# CH32M030 register map
Vendor: WCH Ltd.; File version: 1.1
Registers are 32-bit, read-write, reset 0x0 unless marked. A register's access mark holds for its fields unless they carry their own. Offsets are from the block's base; [hi:lo] are bit positions; {n}, {i} and the like mark numbered series.

## DBG — Debug support
Base 0xE000D000
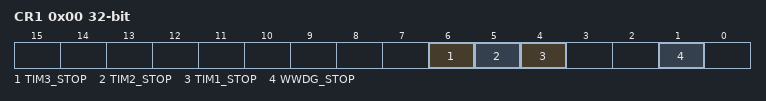
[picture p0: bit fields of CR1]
0x00 CR1 — DBGMCU_CFGR1
  [6] TIM3_STOP, [5] TIM2_STOP, [4] TIM1_STOP, [1] WWDG_STOP

## ESIG — Device electronic signature
Base 0x1FFFF3E0
0x00 FLACAP 16-bit ro — Flash capacity register
  [15:0] F_SIZE_15_0 — Flash size
{0x4+4i} UNIID{i} ro (i=1..3) — Unique identity {i}
  [31:0] U_ID_{32i-1}_{32i-32} — Unique identity[{32i-1}:{32i-32}]

## FLASH
Base 0x40022000
0x00 ACTLR — Flash key register
  [2:0] LATENCY — Number of FLASH wait states
0x04 KEYR wo — Flash key register
  [31:0] KEYR — FPEC key
0x08 OBTKEYR wo — Flash option key register
  [31:0] OBKEYR — Option byte key
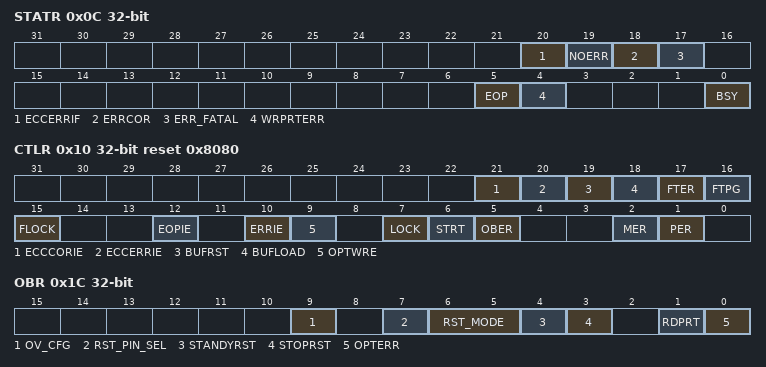
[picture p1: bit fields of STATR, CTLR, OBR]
0x0C STATR access per field — Status register
  [20] ECCERRIF rw — Flash module ECC verification error interrupt flag
  [19] NOERR ro — ECC verification of Flash module is error-free
  [18] ERRCOR ro — Flash module ECC verification error,error correction success
  [17] ERR_FATAL ro — Flash module ECC verification error,error correction success failure
  [5] EOP rw — End of operation
  [4] WRPRTERR rw — Write protection error
  [0] BSY ro — Busy
0x10 CTLR reset 0x8080 — Control register
  [21] ECCCORIE — ECC verification error occurs but correction is successful,ECC error flag location is selected
  [20] ECCERRIE — ECC error interrupt enabled
  [19] BUFRST — Buffer reset
  [18] BUFLOAD — Buffer load
  [17] FTER — Fast erase
  [16] FTPG — Fast programming
  [15] FLOCK — Fast programmable lock
  [12] EOPIE — End of operation interrupt enable
  [10] ERRIE — Error interrupt enable
  [9] OPTWRE — Option bytes lock
  [7] LOCK
  [6] STRT — Start
  [5] OBER — Option byte erase
  [2] MER — Mass Erase
  [1] PER — Page Erase
0x14 ADDR wo — Flash address register
  [31:0] FAR — Flash Address
0x1C OBR ro — Option byte register
  [9] OV_CFG — User configuration bit of the overvoltage protection detection function
  [7] RST_PIN_SEL — RESET PIN selection
  [6:5] RST_MODE — CFG_RST_MODE
  [4] STANDYRST
  [3] STOPRST
  [1] RDPRT — Read protection
  [0] OPTERR — Option byte error
0x20 WPR ro — Write protection register
  [31:0] WRP — Write protect
0x24 MODEKEYR wo — Mode select register
  [31:0] MODEKEYR — Mode select
0x28 BOOT_MODEKEYP wo — Boot mode key register
  [31:0] MODEKEYR — Boot mode key
0x2F CTLR2 8-bit — configuration register 2
  [6:5] VDD8_SEL — VDD voltage selection

## PFIC — Programmable Fast Interrupt Controller
Base 0xE000E000
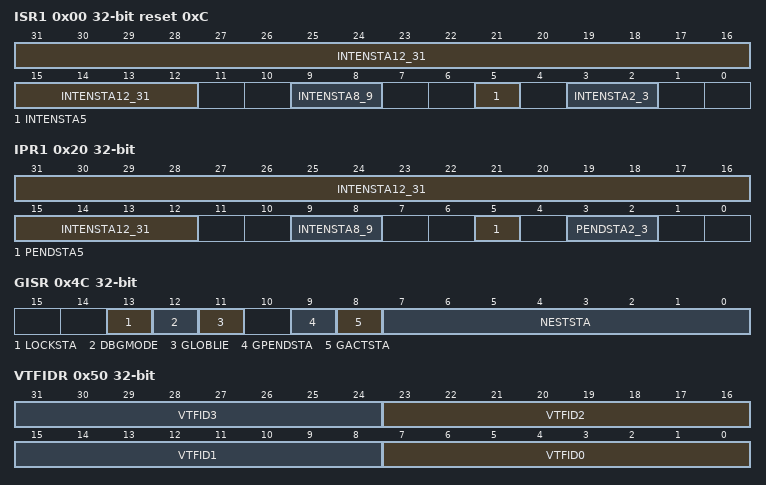
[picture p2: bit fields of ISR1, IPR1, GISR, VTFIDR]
0x00 ISR1 ro reset 0xC — Interrupt Status Register
  [31:12] INTENSTA12_31 — Interrupt ID Status
  [9:8] INTENSTA8_9 — Interrupt ID Status
  [5] INTENSTA5 — Interrupt ID Status
  [3:2] INTENSTA2_3 — Interrupt ID Status
0x04 ISR2 ro — Interrupt Status Register
  [14:0] INTENSTA — Interrupt ID Status
0x20 IPR1 ro — Interrupt Pending Register
  [31:12] INTENSTA12_31 — PENDSTA
  [9:8] INTENSTA8_9 — PENDSTA
  [5] PENDSTA5 — PENDSTA
  [3:2] PENDSTA2_3 — PENDSTA
0x24 IPR2 ro — Interrupt Pending Register
  [14:0] PENDSTA
0x40 ITHRESDR — Interrupt Priority Register
  [7:0] THRESHOLD
0x4C GISR ro — Interrupt Global Register
  [13] LOCKSTA — lock-out state
  [12] DBGMODE — debug mode
  [11] GLOBLIE — global interrupt enable
  [9] GPENDSTA — interrupt pending
  [8] GACTSTA — interrupt execution
  [7:0] NESTSTA — interrupt nesting
0x50 VTFIDR — ID Config Register
  [8n+7:8n] VTFID{n} (n=0..3)
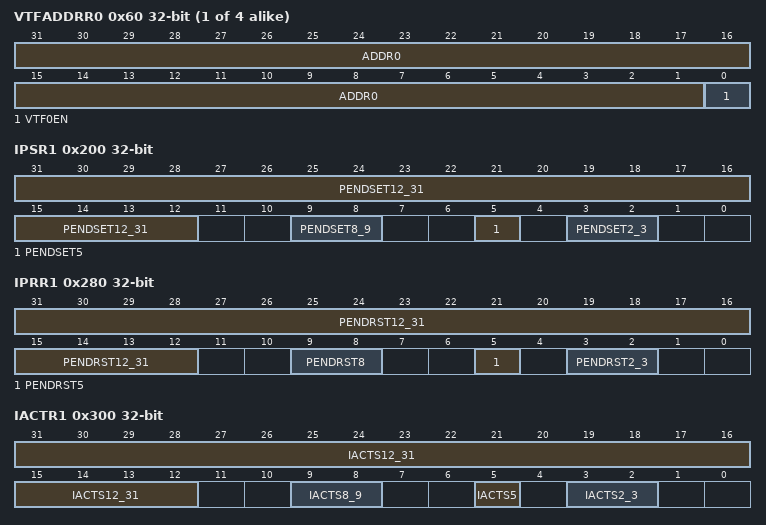
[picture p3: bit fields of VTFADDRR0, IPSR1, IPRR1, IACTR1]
{0x60+4i} VTFADDRR{i} (i=0..3) — Interrupt {i} address Register
  [31:1] ADDR{i}, [0] VTF{i}EN
0x100 IENR1 wo — Interrupt Setting Register
  [31:12] INTEN12_31
0x104 IENR2 wo — Interrupt Setting Register
  [14:0] INTEN — INTEN32_46
0x180 IRER1 wo — Interrupt Clear Register
  [31:12] INTRSET12_31
0x184 IRER2 wo — Interrupt Clear Register
  [14:0] INTRSET — INTRSET38_46
0x200 IPSR1 wo — Interrupt Pending Register
  [31:12] PENDSET12_31 — PENDSET
  [9:8] PENDSET8_9 — PENDSET
  [5] PENDSET5 — PENDSET
  [3:2] PENDSET2_3 — PENDSET
0x204 IPSR2 wo — Interrupt Pending Register
  [14:0] PENDSET — PENDSET32_46
0x280 IPRR1 wo — Interrupt Pending Clear Register
  [31:12] PENDRST12_31 — PENDRESET
  [9:8] PENDRST8 — PENDRESET
  [5] PENDRST5 — PENDRESET
  [3:2] PENDRST2_3 — PENDRESET
0x284 IPRR2 wo — Interrupt Pending Clear Register
  [14:0] PENDRST — PENDRESET32_46
0x300 IACTR1 wo — Interrupt ACTIVE Register
  [31:12] IACTS12_31 — IACTS
  [9:8] IACTS8_9 — IACTS
  [5] IACTS5 — IACTS
  [3:2] IACTS2_3 — IACTS
0x304 IACTR2 wo — Interrupt ACTIVE Register
  [14:0] IACTS — IACTS32_46
{0x400+i} IPRIOR{i} 8-bit (i=0..63) — Interrupt Priority Register
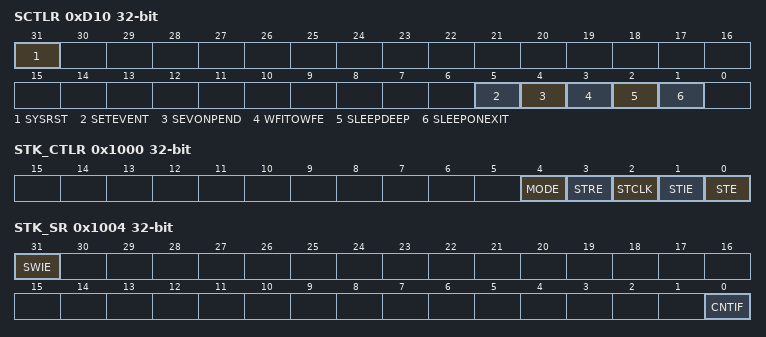
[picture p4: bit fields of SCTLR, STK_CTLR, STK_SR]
0xD10 SCTLR — System Control Register
  [31] SYSRST — System reset
  [5] SETEVENT
  [4] SEVONPEND
  [3] WFITOWFE — ues WFI as WFE
  [2] SLEEPDEEP — low power mode selection
  [1] SLEEPONEXIT — system leaves the state after an interruption
0x1000 STK_CTLR — System counter control register
  [4] MODE — Counting mode
  [3] STRE — System reload register
  [2] STCLK — System selects the clock source
  [1] STIE — System counter interrupt enable
  [0] STE — System counter enable
0x1004 STK_SR — System START
  [31] SWIE — System software triggered interrupts enable
  [0] CNTIF — count value comparsion flag
0x1008 STK_CNTL — System counter low register
  [31:0] CNT
0x1010 STK_CMPLR — System compare low register
  [31:0] CMP
